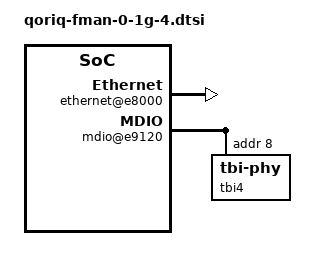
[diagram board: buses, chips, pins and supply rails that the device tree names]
// SPDX-License-Identifier: (GPL-2.0+ OR BSD-3-Clause)
/*
 * QorIQ FMan 1g port #4 device tree stub [ controller @ offset 0x400000 ]
 *
 * Copyright 2011 - 2015 Freescale Semiconductor Inc.
 * Copyright 2020 NXP
 *
 */

fman@400000 {
	fman0_rx_0x0c: port@8c000 {
		cell-index = <0xc>;
		compatible = "fsl,fman-v2-port-rx";
		reg = <0x8c000 0x1000>;
	};

	fman0_tx_0x2c: port@ac000 {
		cell-index = <0x2c>;
		compatible = "fsl,fman-v2-port-tx";
		reg = <0xac000 0x1000>;
	};

	ethernet@e8000 {
		cell-index = <4>;
		compatible = "fsl,fman-dtsec";
		reg = <0xe8000 0x1000>;
		fsl,fman-ports = <&fman0_rx_0x0c &fman0_tx_0x2c>;
		tbi-handle = <&tbi4>;
		ptp-timer = <&ptp_timer0>;
	};

	mdio@e9120 {
		#address-cells = <1>;
		#size-cells = <0>;
		compatible = "fsl,fman-mdio";
		reg = <0xe9120 0xee0>;

		tbi4: tbi-phy@8 {
			reg = <0x8>;
			device_type = "tbi-phy";
		};
	};
};
